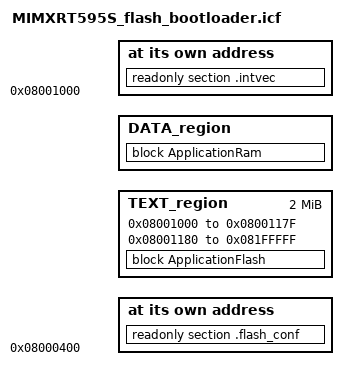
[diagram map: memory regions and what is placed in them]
/*
** ###################################################################
**     Processors:          MIMXRT595SFAWC_cm33
**                          MIMXRT595SFFOC_cm33
**
**     Compiler:            IAR ANSI C/C++ Compiler for ARM
**     Reference manual:    iMXRT500RM Rev.D, 11/2020
**     Version:             rev. 4.0, 2020-05-12
**     Build:               b201117
**
**     Abstract:
**         Linker file for the IAR ANSI C/C++ Compiler for ARM
**
**     Copyright 2016 Freescale Semiconductor, Inc.
**     Copyright 2016-2020 NXP
**     All rights reserved.
**
**     SPDX-License-Identifier: BSD-3-Clause
**
**     http:                 www.nxp.com
**     mail:                 support@nxp.com
**
** ###################################################################
*/

/* USB BDT size */
define symbol usb_bdt_size             = 0x0;
/* Stack and Heap Sizes */
if (isdefinedsymbol(__stack_size__)) {
  define symbol __size_cstack__        = __stack_size__;
} else {
  define symbol __size_cstack__        = 0x1000;
}

if (isdefinedsymbol(__heap_size__)) {
  define symbol __size_heap__          = __heap_size__;
} else {
  define symbol __size_heap__          = 0x0400;
}

/* The SRAM region [0x10000-0x1BFFF] is reserved for ROM code. */
/* The SRAM region [0x0-0xFFFF], [0x1C000-0x1FFFF] are reserved for app-specific use cases. */
/* The SRAM region [0x20000-0x7FFFF] is reserved for Non-cached shared memory between M33 and DSP. */

define symbol __ram_vector_table_size__        =  isdefinedsymbol(__ram_vector_table__) ? 0x00000180 : 0;
define symbol __ram_vector_table_offset__      =  isdefinedsymbol(__ram_vector_table__) ? 0x0000017F : 0;

define symbol m_interrupts_start               = 0x08001000;
define symbol m_interrupts_end                 = 0x0800117F;

define symbol m_text_start                     = 0x08001180;
define symbol m_text_end                       = 0x081FFFFF;

define symbol m_interrupts_ram_start           = 0x20080000;
define symbol m_interrupts_ram_end             = 0x20080000 + __ram_vector_table_offset__;

define symbol m_data_start                     = m_interrupts_ram_start + __ram_vector_table_size__;
define symbol m_data_end                       = 0x202FFFFF;

define symbol m_usb_sram_start                 = 0x40140000;
define symbol m_usb_sram_end                   = 0x40143FFF;

define symbol m_boot_flash_conf_start          = 0x08000400;

define exported symbol __VECTOR_TABLE          = m_interrupts_start;
define exported symbol __VECTOR_RAM            = isdefinedsymbol(__ram_vector_table__) ? m_interrupts_ram_start : m_interrupts_start;
define exported symbol __RAM_VECTOR_TABLE_SIZE = __ram_vector_table_size__;

define memory mem with size = 4G;
define region TEXT_region = mem:[from m_interrupts_start to m_interrupts_end]
                          | mem:[from m_text_start to m_text_end];
define region DATA_region = mem:[from m_data_start to m_data_end-__size_cstack__];

define block CSTACK    with alignment = 8, size = __size_cstack__   { };
define block HEAP      with alignment = 8, size = __size_heap__     { };

initialize by copy { readwrite };
initialize by copy { section .data};
initialize by copy { section .textrw };
do not initialize  { section .noinit };

// define block USBGlobal {section m_usb_bdt, section m_usb_global};
define block CodeRelocate { section .textrw_init };
define block CodeRelocateRam { section .textrw };
define block ApplicationFlash { readonly, block CodeRelocate, readonly section .noinit };
define block ApplicationRam { readwrite, block CodeRelocateRam, block CSTACK, block HEAP };
place at address mem: m_interrupts_start    { readonly section .intvec };
keep{section .flash_conf };
place at address mem: m_boot_flash_conf_start    { readonly section .flash_conf };
place in TEXT_region { block ApplicationFlash };
place in DATA_region { block ApplicationRam };

